# CMS32M6510 register map
Vendor: CMS; Series: CMS32M6510; File version: 1.2
CPU: CM0+ r0p1, little endian, no MPU, no FPU, VTOR, 2 interrupt priority bits
Registers are 32-bit, read-write, reset 0x0 unless marked. A register's access mark holds for its fields unless they carry their own. Offsets are from the block's base; [hi:lo] are bit positions; {n}, {i} and the like mark numbered series; 'fields as' and 'values as' point back to an identical list.

## TM40 — General Purpose Timer 4
Base 0x40041D80
{0x0+2i} TCR0{i} (i=0..3) 16-bit ro reset 0xFFFF — Timer count register 0{i}
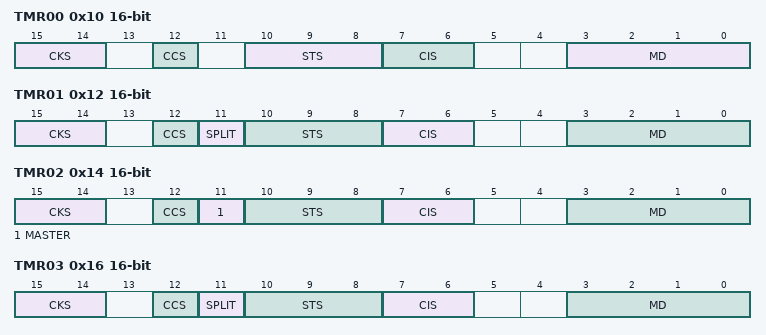
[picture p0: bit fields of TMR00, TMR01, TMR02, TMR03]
0x10 TMR00 16-bit — Timer mode register mn
  [15:14] CKS — Selection of operation clock (fMCK) of channel n
  [12] CCS — Selection of count clock (fTCLK) of channel n
  [10:8] STS — Setting of start trigger or capture trigger of channel n
  [7:6] CIS — Selection of TImn pin input valid edge
  [3:0] MD — Operation mode of channel n
0x12 TMR01 16-bit — Timer mode register mn
  [15:14] CKS — Selection of operation clock (fMCK) of channel n
  [12] CCS — Selection of count clock (fTCLK) of channel n
  [11] SPLIT — Selection of 8 or 16-bit timer operation for channels 1 and 3
  [10:8] STS — Setting of start trigger or capture trigger of channel n
  [7:6] CIS — Selection of TImn pin input valid edge
  [3:0] MD — Operation mode of channel n
0x14 TMR02 16-bit — Timer mode register mn
  [15:14] CKS — Selection of operation clock (fMCK) of channel n
  [12] CCS — Selection of count clock (fTCLK) of channel n
  [11] MASTER — Selection between using channel n independently or simultaneously with another channel (as a slave or master)
  [10:8] STS — Setting of start trigger or capture trigger of channel n
  [7:6] CIS — Selection of TImn pin input valid edge
  [3:0] MD — Operation mode of channel n
0x16 TMR03 16-bit — Timer mode register mn
  fields as TMR01
{0x20+2i} TSR{i:02} 16-bit ro (i=0..3) — Timer status register mn
  [0] OVF — Counter overflow status of channel n
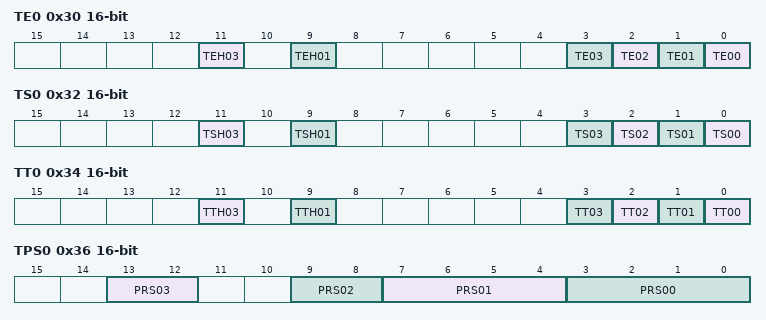
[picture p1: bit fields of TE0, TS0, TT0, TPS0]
0x30 TE0 16-bit ro — Timer channel enable status register m
  [11] TEH03 — Indication of whether operation of the higher 8-bit timer is enabled or stopped when channel 3 is in the 8-bit timer mode
  [9] TEH01 — Indication of whether operation of the higher 8-bit timer is enabled or stopped when channel 1 is in the 8-bit timer mode
  [n] TE{n:02} (n=0..3) — Indication of operation enable/stop status of channel {n}
0x32 TS0 16-bit — Timer channel start register 0
  [11] TSH03 — Trigger to enable operation (start operation) of the higher 8-bit timer when channel 3 is in the 8-bit timer mode
  [9] TSH01 — Trigger to enable operation (start operation) of the higher 8-bit timer when channel 1 is in the 8-bit timer mode
  [n] TS{n:02} (n=0..3) — Operation enable (start) trigger of channel {n}
0x34 TT0 16-bit — Timer channel stop register 0
  [11] TTH03 — Trigger to stop operation of the higher 8-bit timer when channel 3 is in the 8-bit timer mode
  [9] TTH01 — Trigger to stop operation of the higher 8-bit timer when channel 1 is in the 8-bit timer mode
  [n] TT{n:02} (n=0..3) — Operation stop trigger of channel {n}
0x36 TPS0 16-bit — Timer clock select register 0
  [13:12] PRS03 — Prescaler 3
  [9:8] PRS02 — Prescaler 2
  [7:4] PRS01 — Prescaler 1
  [3:0] PRS00 — Prescaler 0
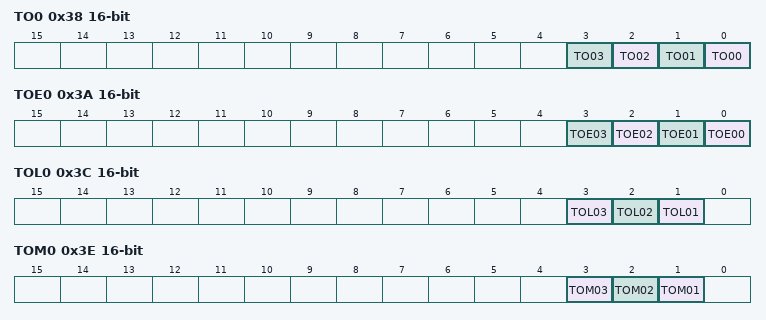
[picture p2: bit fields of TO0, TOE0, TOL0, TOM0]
0x38 TO0 16-bit — Timer output register 0
  [n] TO{n:02} (n=0..3) — Timer output of channel {n}
0x3A TOE0 16-bit — Timer output enable register 0
  [n] TOE{n:02} (n=0..3) — Timer output enable of channel {n}
0x3C TOL0 16-bit — Timer output level register 0
  [3] TOL03 — Control of timer output level of channel 3
  [2] TOL02 — Control of timer output level of channel 2
  [1] TOL01 — Control of timer output level of channel 1
0x3E TOM0 16-bit — Timer output mode register 0
  [3] TOM03 — Control of timer output mode of channel 3
  [2] TOM02 — Control of timer output mode of channel 2
  [1] TOM01 — Control of timer output mode of channel 1
{0x198+2i} TDR0{i} (i=0..1) 16-bit — Timer data register 0{i}
0x19A TDR01L 8-bit (alternate view of TDR01) — Timer data lower register 01
0x19B TDR01H 8-bit (alternate view of TDR01) — Timer data higher register 01
{0x1E0+2i} TDR0{i} (i=2..3) 16-bit — Timer data register 0{i}
0x1E6 TDR03L 8-bit (alternate view of TDR03) — Timer data lower register 03
0x1E7 TDR03H 8-bit (alternate view of TDR03) — Timer data higher register 03
